AUTOSAR XML (schema 00044)
package /ComponentTypes
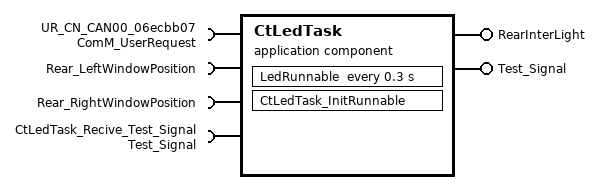
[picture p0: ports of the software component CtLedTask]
  application sw component type CtLedTask
    require port UR_CN_CAN00_06ecbb07: required-com-specs=[RequestComMode, GetCurrentComMode, GetMaxComMode, GetRequestedComMode], required-interface=ComM_UserRequest
    provide port RearInterLight: nonqueued-sender-com-spec{data-element=Bool_signal, init-value=0}, provided-interface=RearInterLight
    require port Rear_LeftWindowPosition: nonqueued-receiver-com-spec{data-element=u8_signal, init-value=0}, required-interface=Rear_LeftWindowPosition
    require port Rear_RightWindowPosition: nonqueued-receiver-com-spec{data-element=u8_signal, init-value=0}, required-interface=Rear_RightWindowPosition
    provide port Test_Signal: nonqueued-sender-com-spec{data-element=u16_Siganl, init-value=0}, provided-interface=Test_Signal
    require port CtLedTask_Recive_Test_Signal: nonqueued-receiver-com-spec{data-element=u16_Siganl, init-value=0}, required-interface=Test_Signal
    behavior CtLedTask_InternalBehavior
      timing event TMT_LedRunnable: start-on-event=LedRunnable, period=0.3
      init event CtLedTask_InitEvent: start-on-event=CtLedTask_InitRunnable
      runnable LedRunnable
        data-receive-point-by-arguments:
          access REC_Rear_LeftWindowPosition_u8_signal: accessed-variable=Rear_LeftWindowPosition.u8_signal
          access REC_Rear_RightWindowPosition_u8_signal: accessed-variable=Rear_RightWindowPosition.u8_signal
          access REC_CtLedTask_Recive_Test_Signal_u16_Siganl: accessed-variable=CtLedTask_Recive_Test_Signal.u16_Siganl
        data-send-points:
          access SEND_RearInterLight_Boo_signal: accessed-variable=RearInterLight.Bool_signal
          access SEND_Test_Signal_u16_Siganl: accessed-variable=Test_Signal.u16_Siganl
      runnable CtLedTask_InitRunnable
        4 x sync call:
          SC_UR_CN_CAN00_06ecbb07_GetCurrentComMode: operation=UR_CN_CAN00_06ecbb07.GetCurrentComMode
          SC_UR_CN_CAN00_06ecbb07_GetMaxComMode: operation=UR_CN_CAN00_06ecbb07.GetMaxComMode
          SC_UR_CN_CAN00_06ecbb07_GetRequestedComMode: operation=UR_CN_CAN00_06ecbb07.GetRequestedComMode
          SC_UR_CN_CAN00_06ecbb07_RequestComMode: operation=UR_CN_CAN00_06ecbb07.RequestComMode
  swc implementation CtLedTask_Implementation: behavior=CtLedTask_InternalBehavior
